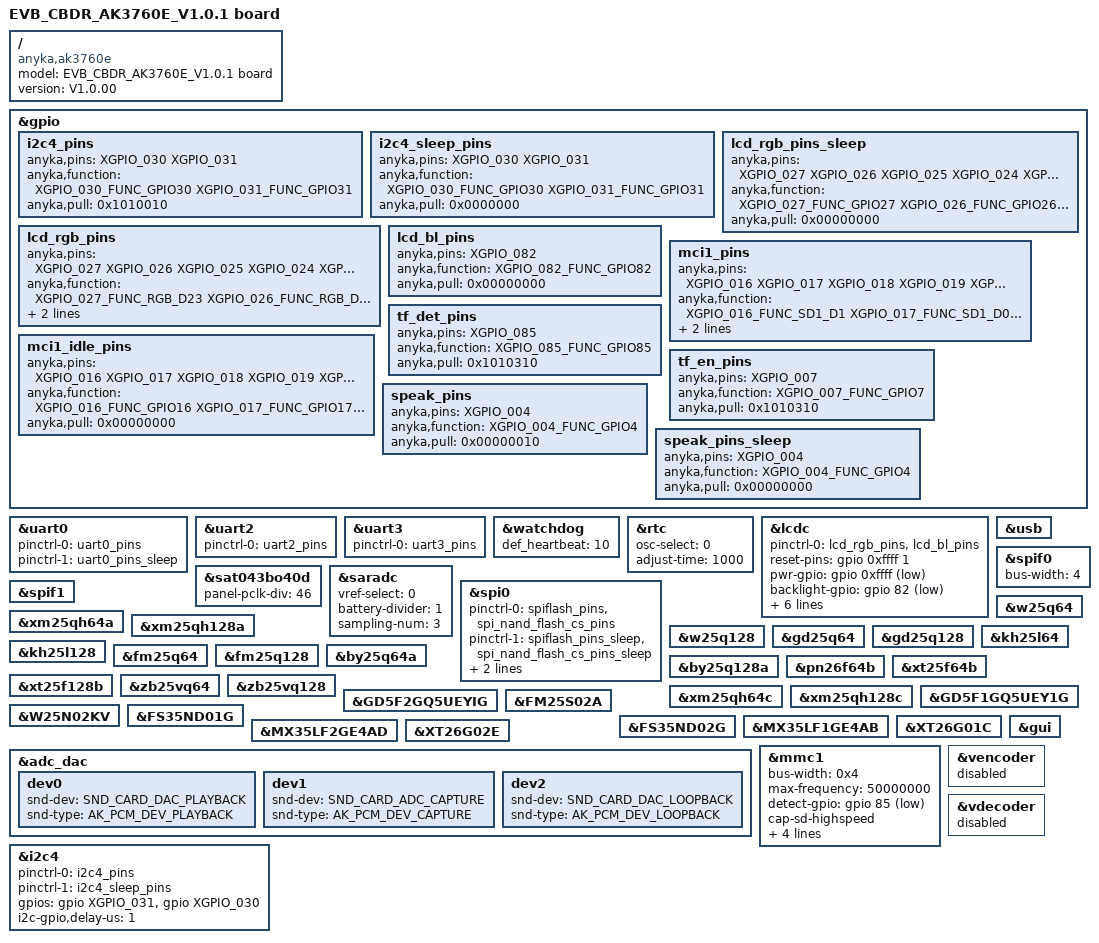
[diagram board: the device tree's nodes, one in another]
/*
 * Anycloud37e dev board dts
 *
 * Copyright (C) 2020 Anyka(Guangzhou) Microelectronics Technology Co., Ltd.
 *
 * This program is free software; you can redistribute it and/or modify
 * it under the terms of the GNU General Public License as published by
 * the Free Software Foundation; either version 2 of the License, or
 * (at your option) any later version.
 *
 * This program is distributed in the hope that it will be useful,
 * but WITHOUT ANY WARRANTY; without even the implied warranty of
 * MERCHANTABILITY or FITNESS FOR A PARTICULAR PURPOSE.  See the
 * GNU General Public License for more details.
 */

/dts-v1/;
#include "anycloud_ak37e.dtsi"
#include "anycloud_norflash.dtsi"
#include "anycloud_nandflash.dtsi"
#include "anycloud_lcd.dtsi"

/ {
    compatible = "anyka,ak3760e";
    model = "EVB_CBDR_AK3760E_V1.0.1 board";
    version = "V1.0.00";
};

&gpio {
    /*
    * "anyka,function": func index, please refer to dt-bindings/pinctrl/ak_37e_pinctrl.h
    * "anyka,pull": configuration of the pins
    * bit[7:0]: pull up/down configuration
    *     bit[0]: pull up or pull down selection, 1 means select pull down, 0 means select pull up
    *     bit[4]: pull up or pull down enable, 1 means enable pull up&down function, 0 means disable fuction
    * !!! Notice that not all pin support pull up and pull down. Please refer to the programer's guide.
    * bit[15:8]: driver strength configuration.
    *     bit[9:8] drive strength.
    * bit[23:16]: input enable configuration
    *     bit[16]: 1 means enable input, 0 means disable input.
    * bit[31:24]: pin slew rate configuration
    *     bit[24]: 1 means enable slew rate, 0 means disable slew rate.
    * !!! Notice OTHER bits which not mentioned please set to 0.
    */

/*
    i2c0_pins: i2c0_pins {
        anyka,pins = <XGPIO_030 XGPIO_031>;
        anyka,function = <XGPIO_030_FUNC_TWI0_SCL XGPIO_031_FUNC_TWI0_SDA>;
        anyka,pull = <0x1010010>;
    };
*/
    /* i2c0_sleep_pins means: pull up or pull down disable; ie disable */
    /*
    i2c0_sleep_pins: i2c0_sleep_pins {
        anyka,pins = <XGPIO_030 XGPIO_031>;
        anyka,function = <XGPIO_030_FUNC_GPIO30 XGPIO_031_FUNC_GPIO31>;
        anyka,pull = <0x0000000>;
    };
*/

    i2c4_pins: i2c4_pins {
        anyka,pins = <XGPIO_030 XGPIO_031>;
        anyka,function = <XGPIO_030_FUNC_GPIO30 XGPIO_031_FUNC_GPIO31>;
        anyka,pull = <0x1010010>;
    };

    /* i2c4_sleep_pins means: pull up or pull down disable; ie disable */
    i2c4_sleep_pins: i2c4_sleep_pins {
        anyka,pins = <XGPIO_030 XGPIO_031>;
        anyka,function = <XGPIO_030_FUNC_GPIO30 XGPIO_031_FUNC_GPIO31>;
        anyka,pull = <0x0000000>;
    };



        lcd_rgb_pins: lcd_rgb_pins {
        anyka,pins = <XGPIO_027
                        XGPIO_026
                        XGPIO_025
                        XGPIO_024
                        XGPIO_028
                        XGPIO_029
                        XGPIO_055
                        XGPIO_054
                        XGPIO_053
                        XGPIO_052
                        XGPIO_051
                        XGPIO_050
                        XGPIO_049
                        XGPIO_048
                        XGPIO_047
                        XGPIO_046
                        XGPIO_045
                        XGPIO_044
                        XGPIO_043
                        XGPIO_042
                        XGPIO_041
                        XGPIO_040
                        XGPIO_039
                        XGPIO_038
                        XGPIO_037
                        XGPIO_036
                        XGPIO_035
                        XGPIO_034>;
        anyka,function = <XGPIO_027_FUNC_RGB_D23
                            XGPIO_026_FUNC_RGB_D22
                            XGPIO_025_FUNC_RGB_D21
                            XGPIO_024_FUNC_RGB_D20
                            XGPIO_028_FUNC_RGB_D19
                            XGPIO_029_FUNC_RGB_D18
                            XGPIO_055_FUNC_RGB_D17
                            XGPIO_054_FUNC_RGB_D16
                            XGPIO_053_FUNC_RGB_D15
                            XGPIO_052_FUNC_RGB_D14
                            XGPIO_051_FUNC_RGB_D13
                            XGPIO_050_FUNC_RGB_D12
                            XGPIO_049_FUNC_RGB_D11
                            XGPIO_048_FUNC_RGB_D10
                            XGPIO_047_FUNC_RGB_D9
                            XGPIO_046_FUNC_RGB_D8
                            XGPIO_045_FUNC_RGB_D7
                            XGPIO_044_FUNC_RGB_D6
                            XGPIO_043_FUNC_RGB_D5
                            XGPIO_042_FUNC_RGB_D4
                            XGPIO_041_FUNC_RGB_D3
                            XGPIO_040_FUNC_RGB_D2
                            XGPIO_039_FUNC_RGB_D1
                            XGPIO_038_FUNC_RGB_D0
                            XGPIO_037_FUNC_RGB_VOPCLK
                            XGPIO_036_FUNC_RGB_VOHSYNC
                            XGPIO_035_FUNC_RGB_VOVSYNC
                            XGPIO_034_FUNC_RGB_VOGATE
                            >;
        anyka,pull = <0x00000110
                        0x00000110
                        0x00000110
                        0x00000110
                        0x00000110
                        0x00000110
                        0x00000110
                        0x00000110
                        0x00000110
                        0x00000110
                        0x00000110
                        0x00000110
                        0x00000110
                        0x00000110
                        0x00000110
                        0x00000110
                        0x00000110
                        0x00000110
                        0x00000110
                        0x00000110
                        0x00000110
                        0x00000110
                        0x00000110
                        0x00000110
                        0x00000010
                        0x00000010
                        0x00000010
                        0x00000010>;
    };

    lcd_rgb_pins_sleep: lcd_rgb_pins_sleep {
        anyka,pins = <XGPIO_027
                        XGPIO_026
                        XGPIO_025
                        XGPIO_024
                        XGPIO_028
                        XGPIO_029
                        XGPIO_055
                        XGPIO_054
                        XGPIO_053
                        XGPIO_052
                        XGPIO_051
                        XGPIO_050
                        XGPIO_049
                        XGPIO_048
                        XGPIO_047
                        XGPIO_046
                        XGPIO_045
                        XGPIO_044
                        XGPIO_043
                        XGPIO_042
                        XGPIO_041
                        XGPIO_040
                        XGPIO_039
                        XGPIO_038
                        XGPIO_037
                        XGPIO_036
                        XGPIO_035
                        XGPIO_034>;
        anyka,function = <XGPIO_027_FUNC_GPIO27
                            XGPIO_026_FUNC_GPIO26
                            XGPIO_025_FUNC_GPIO25
                            XGPIO_024_FUNC_GPIO24
                            XGPIO_028_FUNC_GPIO28
                            XGPIO_029_FUNC_GPIO29
                            XGPIO_055_FUNC_GPIO55
                            XGPIO_054_FUNC_GPIO54
                            XGPIO_053_FUNC_GPIO53
                            XGPIO_052_FUNC_GPIO52
                            XGPIO_051_FUNC_GPIO51
                            XGPIO_050_FUNC_GPIO50
                            XGPIO_049_FUNC_GPIO49
                            XGPIO_048_FUNC_GPIO48
                            XGPIO_047_FUNC_GPIO47
                            XGPIO_046_FUNC_GPIO46
                            XGPIO_045_FUNC_GPIO45
                            XGPIO_044_FUNC_GPIO44
                            XGPIO_043_FUNC_GPIO43
                            XGPIO_042_FUNC_GPIO42
                            XGPIO_041_FUNC_GPIO41
                            XGPIO_040_FUNC_GPIO40
                            XGPIO_039_FUNC_GPIO39
                            XGPIO_038_FUNC_GPIO38
                            XGPIO_037_FUNC_GPIO37
                            XGPIO_036_FUNC_GPIO36
                            XGPIO_035_FUNC_GPIO35
                            XGPIO_034_FUNC_GPIO34
                            >;
        anyka,pull = <0x00000000>;
    };

    lcd_bl_pins: lcd_bl_pins {
        anyka,pins = <XGPIO_082>;
        anyka,function = <XGPIO_082_FUNC_GPIO82>;
        anyka,pull = <0x00000000>;
    };



    mci1_pins: mci1_pins {
        anyka,pins = <XGPIO_016 XGPIO_017 XGPIO_018 XGPIO_019 XGPIO_020 XGPIO_021>;
        anyka,function = <XGPIO_016_FUNC_SD1_D1
                            XGPIO_017_FUNC_SD1_D0
                            XGPIO_018_FUNC_SD1_MCLK
                            XGPIO_019_FUNC_SD1_CMD
                            XGPIO_020_FUNC_SD1_D3
                            XGPIO_021_FUNC_SD1_D2>;
        anyka,pull = <0x00010010 0x00010010 0x00010001 0x00010010 0x00010010 0x00010010>;
    };

    /* mci1_idle_pins  means: pull up or pull down disable; ie disable */
    mci1_idle_pins: mci1_idle_pins {
        anyka,pins = <XGPIO_016 XGPIO_017 XGPIO_018 XGPIO_019 XGPIO_020 XGPIO_021>;
        anyka,function = <XGPIO_016_FUNC_GPIO16
                            XGPIO_017_FUNC_GPIO17
                            XGPIO_018_FUNC_GPIO18
                            XGPIO_019_FUNC_GPIO19
                            XGPIO_020_FUNC_GPIO20
                            XGPIO_021_FUNC_GPIO21>;
        anyka,pull = <0x00000000>;
    };

    tf_det_pins: tf_det_pins{
        anyka,pins = <XGPIO_085>;
        anyka,function = <XGPIO_085_FUNC_GPIO85>;
        anyka,pull = <0x1010310>;
    };

    tf_en_pins: tf_en_pins {
        anyka,pins = <XGPIO_007>;
        anyka,function = <XGPIO_007_FUNC_GPIO7>;
        anyka,pull = <0x1010310>;
    };


    speak_pins: speak_pins {
        anyka,pins = <XGPIO_004>;
        anyka,function = <XGPIO_004_FUNC_GPIO4>;
        anyka,pull = <0x00000010>;
    };

    speak_pins_sleep: speak_pins_sleep {
        anyka,pins = <XGPIO_004>;
        anyka,function = <XGPIO_004_FUNC_GPIO4>;
        anyka,pull = <0x00000000>;
    };



/*
    dvp0_8bits_pins: dvp0_8bits_pins {
        anyka,pins = <XGPIO_060
                        XGPIO_061
                        XGPIO_062
                        XGPIO_063
                        XGPIO_064
                        XGPIO_065
                        XGPIO_066
                        XGPIO_067>;
        anyka,function = <XGPIO_060_FUNC_CSI0_D0
                        XGPIO_061_FUNC_CSI0_D1
                        XGPIO_062_FUNC_CSI0_D2
                        XGPIO_063_FUNC_CSI0_D3
                        XGPIO_064_FUNC_CSI0_D4
                        XGPIO_065_FUNC_CSI0_D5
                        XGPIO_066_FUNC_CSI0_D6
                        XGPIO_067_FUNC_CSI0_D7>;
        anyka,pull = <0x01010310>;
    };
    */
/*
    csi0_sclk_pin: csi0_sclk_pin {
        anyka,pins = <XGPIO_056
                        XGPIO_057
                        XGPIO_058
                        XGPIO_059>;
        anyka,function = <XGPIO_056_FUNC_CSI0_SCLK
                        XGPIO_057_FUNC_CSI0_PCLK
                        XGPIO_058_FUNC_CSI0_HSYNC
                        XGPIO_059_FUNC_CSI0_VSYNC>;
        anyka,pull = <0x01010310>;
    };
    */
/*
    sensor0_reset_pins: sensor0_reset_pins {
        anyka,pins = <XGPIO_032>;
        anyka,function = <XGPIO_032_FUNC_GPIO32>;
        anyka,pull = <0x01000110>;
    };

    sensor0_pwdn_pins: sensor0_pwdn_pins {
        anyka,pins = <XGPIO_071>;
        anyka,function = <XGPIO_071_FUNC_GPIO71>;
        anyka,pull = <0x01000110>;
    };
*/
/*
    pm_wakeup_pins: pm_wakeup_pins {
        anyka,pins = <XGPIO_031>;
        anyka,function = <XGPIO_031_FUNC_GPIO31>;
        anyka,pull = <0x01010210>;
    };
    */
};
/*
&pm_standby {
    pinctrl-names = "default";
    pinctrl-0 = <&pm_wakeup_pins>;
    /* linux kernel standby wakeup mode
    * wakeup mode:0x0:no_src, 0x1:GPIO, 0x2:rtc, 0x3:ain0, 0x4:usb_dm, 0x5:usb_dp
    */
    //wakeup-mode = <0x1>;
    //wakeup-gpio = <&gpio XGPIO_031 1>;
    /*
    * wakeup gpio trigger: 0x0:rising-edge,0x1:falling-edge, 
    */
    //wakeup-gpio-edge = <0x1>;

    /*
    * wakeup ain0 trigger: 0x0:falling-edge, 0x1:rising-edge
    */
    /*wakeup-ain0-edge = <0x0>;

    status = "okay";
};*/

&uart0 {
    pinctrl-names = "default", "sleep";
    pinctrl-0 = <&uart0_pins>;
    pinctrl-1 = <&uart0_pins_sleep>;
    status = "okay";
};

&uart2 {
    pinctrl-names = "default";
    pinctrl-0 = <&uart2_pins>;
    status = "okay";
};

&uart3 {
    pinctrl-names = "default";
    pinctrl-0 = <&uart3_pins>;
    status = "okay";
};


&watchdog {
    /*max feed dog time = 357s, default setting time = 10s. */
    def_heartbeat = <10>;
    status = "okay";
};

&rtc {
    /*
     * rtc osc_source_select, 1 means INTERNAL RC OSC, 0 means EXTERNAL XTAL
     * if internal RC OSC is used to generate 32KH,time adjustment should be setting.(basic unit: ms)
     */
    osc-select = <0>;
    adjust-time = <1000>;
    //adjust-based-on-timer;
    status = "okay";
};



/* RGB panel*/
&lcdc {
    pinctrl-names = "default";//"sleep";
    pinctrl-0 = <&lcd_rgb_pins  &lcd_bl_pins>;
    //pinctrl-1 = <&lcd_rgb_pins_sleep  &lcd_power_pins>;
    reset-pins = <&gpio 0xffff 1>;
    pwr-gpio = <&gpio 0xffff 1>;
    backlight-gpio = <&gpio 82 1>;

    lcd-logo-width = <480>;   // calluse:252  ff:175 152
    lcd-logo-height = <272>;   // calluse:67   ff:104 53
    //[fmt1:fmt0] 00 16bits input(RGB565 or BGR565)
    //[fmt1:fmt0] 01 24bits input(RGB888 or BGR888)
    //[fmt1:fmt0] 10 or 11 32bits input(ARGB888 ABGR888 RGBA888 BGRA888)
    lcd-logo-fmt0 = <1>;
    lcd-logo-fmt1 = <0>;
    lcd-logo-rgb-seq = <0>; //0 for BGR, 1 for RGB

    lcd-fb-type = <1>; //0:single buffer; 1:double buffer
    status = "okay";
};

/* 4.3 inch rgb */
&sat043bo40d {
    panel-pclk-div = <46>;
    status = "okay";
};

&saradc{
    /* SAR ADC VREF selection
    * 0:To select AVCC 3.3V as VREF for SAR ADC.
    * 1:To select 3.0V generated from BGR as VREF for SAR ADC.
    */
    vref-select = <0>;
    /*
    * 0:To disable BAT voltage divider.
    * 1:To enable BAT voltage divider divided by 2.
    */
    battery-divider = <1>;
    /*
    * Sampling number
    * Read the sampling data for N times and then calculate the average value.
    * N ranges from 1 to 7.
    */
    sampling-num = <3>;
    status = "okay";
};

&usb {
    status = "okay";
};

&spi0 {
    pinctrl-names = "default","sleep";
    pinctrl-0 = <&spiflash_pins &spi_nand_flash_cs_pins>;
    pinctrl-1 = <&spiflash_pins_sleep &spi_nand_flash_cs_pins_sleep>;
    spi-bus-frequency = <80000000>;
    /*
     * cap-spi-highspeed;
     * if defined, means high speed controller(Maximum 80M/s);
     * if not, means normal speed controller(below 60M/s)
     */
    cap-spi-highspeed;
    status = "okay";
};

&spif0 {
    /* spi flash data bus width:
    ** 1 means 1 wire mode.
    ** 2 means 2 wire mode
    ** 4 means 4 wire mode.
    ** default: 4 wire mode.
    **/
    bus-width = <4>;
    status = "okay";
};

&spif1 {
    status = "okay";
};

&xm25qh64a{
    status = "okay";
};

&xm25qh128a{
    status = "okay";
};

&w25q64{
    status = "okay";
};

&w25q128{
    status = "okay";
};

&gd25q64{
    status = "okay";
};

&gd25q128{
    status = "okay";
};

&kh25l64{
    status = "okay";
};

&kh25l128{
    status = "okay";
};

&fm25q64{
    status = "okay";
};

&fm25q128{
    status = "okay";
};

&by25q64a{
    status = "okay";
};

&by25q128a{
    status = "okay";
};

&pn26f64b{
    status = "okay";
};

&xt25f64b{
    status = "okay";
};

&xt25f128b{
    status = "okay";
};

&zb25vq64{
    status = "okay";
};

&zb25vq128{
    status = "okay";
};

&xm25qh64c{
    status = "okay";
};

&xm25qh128c{
    status = "okay";
};

&GD5F1GQ5UEY1G{
    status = "okay";
};

&GD5F2GQ5UEYIG{
    status = "okay";
};

&FM25S02A{
    status = "okay";
};

&W25N02KV{
    status = "okay";
};

&FS35ND01G{
    status = "okay";
};

&FS35ND02G{
    status = "okay";
};

&MX35LF1GE4AB{
    status = "okay";
};

&XT26G01C{
    status = "okay";
};

&MX35LF2GE4AD{
    status = "okay";
};

&XT26G02E{
    status = "okay";
};

&adc_dac {
    //pinctrl-names = "default", "sleep", "pdm_pins";
    //pinctrl-0 = <&speak_pins>;
    //pinctrl-1 = <&speak_pins_sleep>;
    //pinctrl-2 = <&pdm_pins>;
    //speak-gpios = <&gpio XGPIO_072 1>;
    /*
    * The level of speak-gpios votage for power on audio: 0=low, 1=high
    */
    //speak-gpios-en = <1>;
    status = "okay";

    dev0 {
        snd-dev = <SND_CARD_DAC_PLAYBACK>;
        snd-type = <AK_PCM_DEV_PLAYBACK>;
    };

    dev1 {
        snd-dev = <SND_CARD_ADC_CAPTURE>;
        snd-type = <AK_PCM_DEV_CAPTURE>;
    };

    dev2 {
        snd-dev = <SND_CARD_DAC_LOOPBACK>;
        snd-type = <AK_PCM_DEV_LOOPBACK>;
    };
};


&gui{
    status = "okay";
};


&mmc1 {
    bus-width = <0x4>;
    max-frequency = <50000000>;
    /*
     *  detect mode:
     *  (1) non-removable;
     *  (2) detect-gpio/detect-gpios: card detect using gpio
     *      for example:
     *      detect-gpio = <&gpio 76 1>;  or detect-gpios = <&gpio 76 1>;
     *  (3) cd_clk: card detect using MCLK
     */
    detect-gpio = <&gpio 85 1>;
    /* if support highspeed, using cap-sd-highspeed */
    cap-sd-highspeed;
    pinctrl-names = "default","idle";
    /*pinctrl-0 = <&mci1_pins>,<&tf_en_pins>;*/
    pinctrl-0 = <&mci1_pins>,<&tf_en_pins>,<&tf_det_pins>;
    pinctrl-1 = <&mci1_idle_pins>;
    /*
    * support tf card circuit enable function
    */
    power-pins = <&gpio 7 1>;      //power-pins is which tf_en_pins describes
    power-inverted;
    status = "okay";
};

&vencoder {
    status = "disable";
};

&vdecoder{
    status = "disable";
};



/*
&i2c0 {
    pinctrl-names = "default","sleep";
    pinctrl-0 = <&i2c0_pins>;
    pinctrl-1 = <&i2c0_sleep_pins>;

    clock-frequency = <400000>;
    sda-delay = <100>;
    status = "okay";
    #address-cells = <1>;
    #size-cells = <0>;

    sensor0: camera@0x42{
        compatible = "anyka,sensor0";
        reg = <0x42>;
        pinctrl-names = "default";
        pinctrl-0 = <&sensor0_reset_pins &sensor0_pwdn_pins>;
        /*
        * 0xFFFF means the gpio is invalid
        */
        /*
        reset-gpio = <&gpio XGPIO_032 1>;
        pwdn-gpio = <&gpio XGPIO_071 1>;

        port {
            sensor0_0: endpoint@0 {
                remote-endpoint = <&vi_0_0>;
            };
        };
    };
};
*/


&i2c4 {
    pinctrl-names = "default","sleep";
    pinctrl-0 = <&i2c4_pins>;
    pinctrl-1 = <&i2c4_sleep_pins>;

    /*
    * SDA -- SCL
    */
    gpios = <&gpio XGPIO_031 GPIO_ACTIVE_HIGH
             &gpio XGPIO_030 GPIO_ACTIVE_HIGH
            >;


    /*clock-frequency = <100000>;
    sda-delay = <100>;
    */
    i2c-gpio,delay-us = <1>;
    status = "okay";
    /*
    sensor0: camera@0x45{
        compatible = "anyka,sensor0";
        reg = <0x45>;
        pinctrl-names = "default";
        pinctrl-0 = <&sensor0_reset_pins>;
        /*
        * 0xFFFF means the gpio is invalid
        */
        /*
        reset-gpio = <&gpio XGPIO_032 1>;

        port {
            sensor0_0: endpoint@0 {
                remote-endpoint = <&vi_0_0>;
            };
        };
    };
    */
};
/*
&vi0 {
    pinctrl-names = "default", "dvp0_8bits", "csi0_sclk";
    pinctrl-0 = <&dvp0_8bits_pins &csi0_sclk_pin>;
    pinctrl-1 = <&dvp0_8bits_pins>;
    pinctrl-2 = <&csi0_sclk_pin>;
    status = "disable";

    port@0 {
        #address-cells = <1>;
        #size-cells = <0>;

        vi_0_0: endpoint@0 {
            reg = <0>;
            remote-endpoint = <&sensor0_0>;
        };
    };
};
*/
